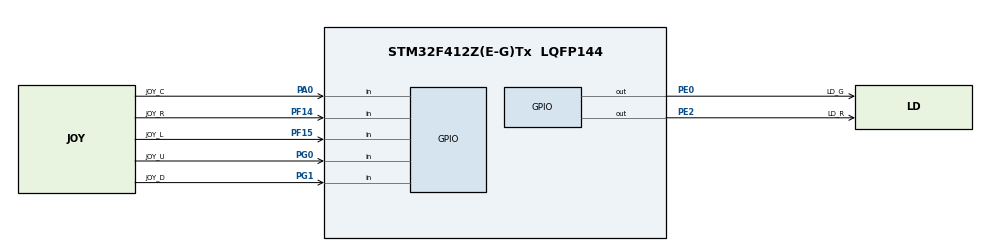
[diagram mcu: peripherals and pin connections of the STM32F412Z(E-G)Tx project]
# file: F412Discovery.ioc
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Mcu.Family=STM32F4
Mcu.Name=STM32F412Z(E-G)Tx
Mcu.Package=LQFP144
NVIC.PriorityGroup=NVIC_PRIORITYGROUP_4
PA0.GPIO_Label=JOY_C
PA0.GPIO_Mode=GPIO_MODE_INPUT
PA0.GPIO_PuPd=GPIO_PULLDOWN
PA0.Signal=GPIO_Input
PA13.Mode=Serial_Wire
PA13.Signal=SYS_JTMS-SWDIO
PA14.Mode=Serial_Wire
PA14.Signal=SYS_JTCK-SWCLK
PE0.GPIO_Label=LD_G
PE0.GPIO_ModeDefaultOutputPP=GPIO_MODE_OUTPUT_OD
PE0.PinState=GPIO_PIN_SET
PE0.Signal=GPIO_Output
PE2.GPIO_Label=LD_R
PE2.GPIO_ModeDefaultOutputPP=GPIO_MODE_OUTPUT_OD
PE2.PinState=GPIO_PIN_SET
PE2.Signal=GPIO_Output
PF14.GPIO_Label=JOY_R
PF14.GPIO_PuPd=GPIO_PULLDOWN
PF14.Signal=GPIO_Input
PF15.GPIO_Label=JOY_L
PF15.GPIO_PuPd=GPIO_PULLDOWN
PF15.Signal=GPIO_Input
PG0.GPIO_Label=JOY_U
PG0.GPIO_PuPd=GPIO_PULLDOWN
PG0.Signal=GPIO_Input
PG1.GPIO_Label=JOY_D
PG1.GPIO_Mode=GPIO_MODE_INPUT
PG1.GPIO_PuPd=GPIO_PULLDOWN
PG1.Signal=GPIO_Input
ProjectManager.HeapSize=0x200
ProjectManager.StackSize=0x400
ProjectManager.TargetToolchain=MDK-ARM V5.27
RCC.CortexFreq_Value=16000000
RCC.USBFreq_Value=96000000
RCC.VCOOutputFreq_Value=192000000
board=custom

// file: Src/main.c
/* USER CODE BEGIN Header */
/**
  ******************************************************************************
  * @file           : main.c
  * @brief          : Main program body
  ******************************************************************************
  * @attention
  *
  * <h2><center>&copy; Copyright (c) 2021 STMicroelectronics.
  * All rights reserved.</center></h2>
  *
  * This software component is licensed by ST under BSD 3-Clause license,
  * the "License"; You may not use this file except in compliance with the
  * License. You may obtain a copy of the License at:
  *                        opensource.org/licenses/BSD-3-Clause
  *
  ******************************************************************************
  */
/* USER CODE END Header */
#include "main.h"

/* USER CODE BEGIN Includes */
#include "usr_tasks.h"

/* USER CODE END Includes */

void SystemClock_Config(void);
static void MX_GPIO_Init(void);

int main(void)
{

  /* MCU Configuration--------------------------------------------------------*/

  /* Reset of all peripherals, Initializes the Flash interface and the Systick. */
  HAL_Init();

  /* Configure the system clock */
  SystemClock_Config();

  /* Initialize all configured peripherals */
  MX_GPIO_Init();
  /* USER CODE BEGIN 2 */
void USR_Task_LD_R_on_LD_G_off(void);
  /* USER CODE END 2 */

  /* Infinite loop */
  while (1)
  {

    /* USER CODE BEGIN 3 */
        USR_Task_RunLoop();
  }
  /* USER CODE END 3 */
}

void SystemClock_Config(void)
{
  RCC_OscInitTypeDef RCC_OscInitStruct = {0};
  RCC_ClkInitTypeDef RCC_ClkInitStruct = {0};

  /** Configure the main internal regulator output voltage
  */
  __HAL_RCC_PWR_CLK_ENABLE();
  __HAL_PWR_VOLTAGESCALING_CONFIG(PWR_REGULATOR_VOLTAGE_SCALE1);
  /** Initializes the RCC Oscillators according to the specified parameters
  * in the RCC_OscInitTypeDef structure.
  */
  RCC_OscInitStruct.OscillatorType = RCC_OSCILLATORTYPE_HSI;
  RCC_OscInitStruct.HSIState = RCC_HSI_ON;
  RCC_OscInitStruct.HSICalibrationValue = RCC_HSICALIBRATION_DEFAULT;
  RCC_OscInitStruct.PLL.PLLState = RCC_PLL_NONE;
  if (HAL_RCC_OscConfig(&RCC_OscInitStruct) != HAL_OK)
  {
    Error_Handler();
  }
  /** Initializes the CPU, AHB and APB buses clocks
  */
  RCC_ClkInitStruct.ClockType = RCC_CLOCKTYPE_HCLK|RCC_CLOCKTYPE_SYSCLK
                              |RCC_CLOCKTYPE_PCLK1|RCC_CLOCKTYPE_PCLK2;
  RCC_ClkInitStruct.SYSCLKSource = RCC_SYSCLKSOURCE_HSI;
  RCC_ClkInitStruct.AHBCLKDivider = RCC_SYSCLK_DIV1;
  RCC_ClkInitStruct.APB1CLKDivider = RCC_HCLK_DIV1;
  RCC_ClkInitStruct.APB2CLKDivider = RCC_HCLK_DIV1;

  if (HAL_RCC_ClockConfig(&RCC_ClkInitStruct, FLASH_LATENCY_0) != HAL_OK)
  {
    Error_Handler();
  }
}

static void MX_GPIO_Init(void)
{
  GPIO_InitTypeDef GPIO_InitStruct = {0};

  /* GPIO Ports Clock Enable */
  __HAL_RCC_GPIOE_CLK_ENABLE();
  __HAL_RCC_GPIOA_CLK_ENABLE();
  __HAL_RCC_GPIOF_CLK_ENABLE();
  __HAL_RCC_GPIOG_CLK_ENABLE();

  /*Configure GPIO pin Output Level */
  HAL_GPIO_WritePin(GPIOE, LD_R_Pin|LD_G_Pin, GPIO_PIN_SET);

  /*Configure GPIO pins : LD_R_Pin LD_G_Pin */
  GPIO_InitStruct.Pin = LD_R_Pin|LD_G_Pin;
  GPIO_InitStruct.Mode = GPIO_MODE_OUTPUT_OD;
  GPIO_InitStruct.Pull = GPIO_NOPULL;
  GPIO_InitStruct.Speed = GPIO_SPEED_FREQ_LOW;
  HAL_GPIO_Init(GPIOE, &GPIO_InitStruct);

  /*Configure GPIO pin : JOY_C_Pin */
  GPIO_InitStruct.Pin = JOY_C_Pin;
  GPIO_InitStruct.Mode = GPIO_MODE_INPUT;
  GPIO_InitStruct.Pull = GPIO_PULLDOWN;
  HAL_GPIO_Init(JOY_C_GPIO_Port, &GPIO_InitStruct);

  /*Configure GPIO pins : JOY_R_Pin JOY_L_Pin */
  GPIO_InitStruct.Pin = JOY_R_Pin|JOY_L_Pin;
  GPIO_InitStruct.Mode = GPIO_MODE_INPUT;
  GPIO_InitStruct.Pull = GPIO_PULLDOWN;
  HAL_GPIO_Init(GPIOF, &GPIO_InitStruct);

  /*Configure GPIO pins : JOY_U_Pin JOY_D_Pin */
  GPIO_InitStruct.Pin = JOY_U_Pin|JOY_D_Pin;
  GPIO_InitStruct.Mode = GPIO_MODE_INPUT;
  GPIO_InitStruct.Pull = GPIO_PULLDOWN;
  HAL_GPIO_Init(GPIOG, &GPIO_InitStruct);

}

void Error_Handler(void)
{
  __disable_irq();
  while (1)
  {
  }
}

/************************ (C) COPYRIGHT STMicroelectronics *****END OF FILE****/
